# FCFG1 register map
Vendor: Texas Instruments
Peripheral module from a debugger description file (folder CC2650).
Registers are 32-bit, read-only, reset 0xFFFFFFFF unless marked. A register's access mark holds for its fields unless they carry their own. Offsets are as the file gives them; lines under a group give offsets from that group; [hi:lo] are bit positions; {n}, {i} and the like mark numbered series; 'fields as' and 'values as' point back to an identical list; <NAME> marks a mode.

## FCFG1 — Factory configuration area (FCFG1)
0xA0 MISC_CONF_1 reset 0xFFFFFF00 — Misc configurations
  [7:0] DEVICE_MINOR_REV — HW minor revision number (a value of 0xFF is treated equally to 0x00). Value may change without warning.
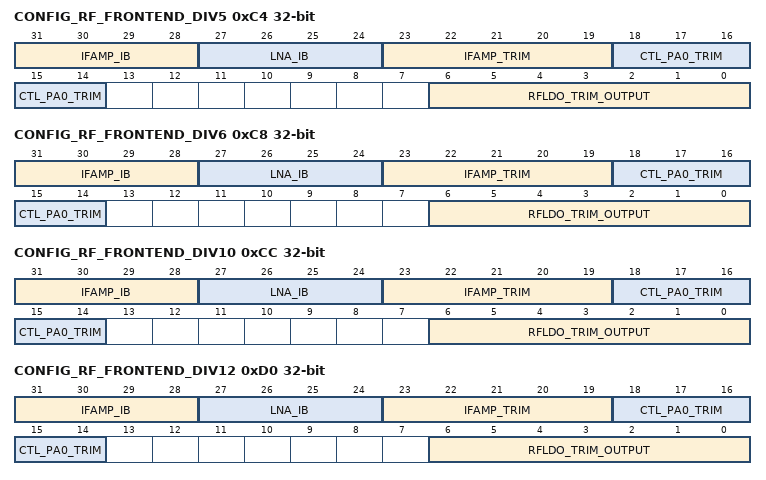
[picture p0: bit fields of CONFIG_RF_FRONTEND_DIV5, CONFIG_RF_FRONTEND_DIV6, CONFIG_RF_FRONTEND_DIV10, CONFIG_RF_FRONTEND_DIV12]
0xC4 CONFIG_RF_FRONTEND_DIV5 — Configuration of RF Frontend in Divide-by-5 Mode Divide-by-5 mode is only available for CC13xx.
  [31:28] IFAMP_IB — Trim value used for ADI_0_RF:IFAMPCTL3.IB. Value is read by RF Core ROM FW during RF Core initialization.
  [27:24] LNA_IB — Trim value for ADI_0_RF:LNACTL2.IB. Value is read by RF Core ROM FW during RF Core initialization.
  [23:19] IFAMP_TRIM — Trim value for ADI_0_RF:IFAMPCTL0.TRIM. Value is read by RF Core ROM FW during RF Core initialization.
  [18:14] CTL_PA0_TRIM — Trim value for ADI_0_RF:PACTL0.TRIM. Value is read by RF Core ROM FW during RF Core initialization.
  [6:0] RFLDO_TRIM_OUTPUT — Trim value for ADI_0_RF:RFLDO1.TRIM_OUT. Value is read by RF Core ROM FW during RF Core initialization.
0xC8 CONFIG_RF_FRONTEND_DIV6 — Configuration of RF Frontend in Divide-by-6 Mode Divide-by-6 mode is only available for CC13xx.
  fields as CONFIG_RF_FRONTEND_DIV5
0xCC CONFIG_RF_FRONTEND_DIV10 — Configuration of RF Frontend in Divide-by-10 Mode Divide-by-10 mode is only available for CC13xx.
  fields as CONFIG_RF_FRONTEND_DIV5
0xD0 CONFIG_RF_FRONTEND_DIV12 — Configuration of RF Frontend in Divide-by-12 Mode Divide-by-12 mode is only available for CC13xx.
  fields as CONFIG_RF_FRONTEND_DIV5
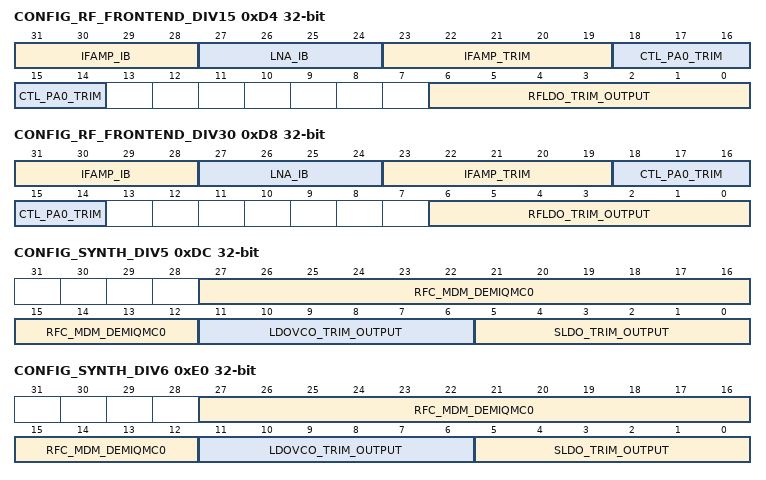
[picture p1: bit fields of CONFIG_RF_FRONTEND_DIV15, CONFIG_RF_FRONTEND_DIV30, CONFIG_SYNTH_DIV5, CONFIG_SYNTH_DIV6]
0xD4 CONFIG_RF_FRONTEND_DIV15 — Configuration of RF Frontend in Divide-by-15 Mode Divide-by-15 mode is only available for CC13xx.
  fields as CONFIG_RF_FRONTEND_DIV5
0xD8 CONFIG_RF_FRONTEND_DIV30 — Configuration of RF Frontend in Divide-by-30 Mode Divide-by-30 mode is only available for CC13xx.
  fields as CONFIG_RF_FRONTEND_DIV5
0xDC CONFIG_SYNTH_DIV5 — Configuration of Synthesizer in Divide-by-5 Mode Divide-by-5 mode is only available for CC13xx.
  [27:12] RFC_MDM_DEMIQMC0 — Trim value for RFC_MDM:DEMIQMC0.GAINFACTOR and RFC_MDM:DEMIQMC0.PHASEFACTOR Value is read by RF Core ROM FW during RF Core initialization.
  [11:6] LDOVCO_TRIM_OUTPUT — Trim value for ADI_1_SYNTH:VCOLDOCTL1.TRIM_OUT. Value is read by RF Core ROM FW during RF Core initialization.
  [5:0] SLDO_TRIM_OUTPUT — Trim value for ADI_1_SYNTH:SLDOCTL1.TRIM_OUT. Value is read by RF Core ROM FW during RF Core initialization.
0xE0 CONFIG_SYNTH_DIV6 — Configuration of Synthesizer in Divide-by-6 Mode Divide-by-6 mode is only available for CC13xx.
  fields as CONFIG_SYNTH_DIV5
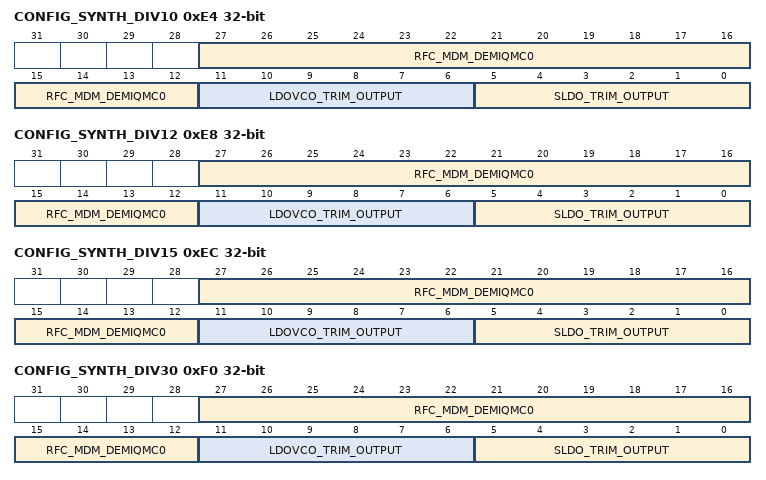
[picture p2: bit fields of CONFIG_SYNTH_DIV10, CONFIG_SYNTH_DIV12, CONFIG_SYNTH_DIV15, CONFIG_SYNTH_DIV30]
0xE4 CONFIG_SYNTH_DIV10 — Configuration of Synthesizer in Divide-by-10 Mode Divide-by-10 mode is only available for CC13xx.
  fields as CONFIG_SYNTH_DIV5
0xE8 CONFIG_SYNTH_DIV12 — Configuration of Synthesizer in Divide-by-12 Mode Divide-by-12 mode is only available for CC13xx.
  fields as CONFIG_SYNTH_DIV5
0xEC CONFIG_SYNTH_DIV15 — Configuration of Synthesizer in Divide-by-15 Mode Divide-by-15 mode is only available for CC13xx.
  fields as CONFIG_SYNTH_DIV5
0xF0 CONFIG_SYNTH_DIV30 — Configuration of Synthesizer in Divide-by-30 Mode Divide-by-30 mode is only available for CC13xx.
  fields as CONFIG_SYNTH_DIV5
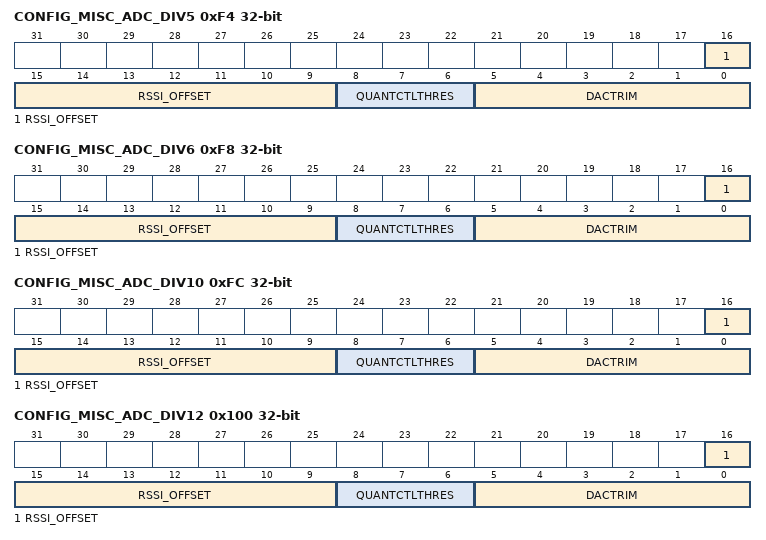
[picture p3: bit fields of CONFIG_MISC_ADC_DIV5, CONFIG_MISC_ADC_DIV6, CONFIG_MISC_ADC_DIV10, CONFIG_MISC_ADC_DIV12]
0xF4 CONFIG_MISC_ADC_DIV5 — Configuration of IFADC in Divide-by-5 Mode Divide-by-5 mode is only available for CC13xx.
  [16:9] RSSI_OFFSET — Value for RSSI measured in production test. Value is read by RF Core ROM FW during RF Core initialization.
  [8:6] QUANTCTLTHRES — Trim value for ADI_0_RF:IFADCQUANT0.TH. Value is read by RF Core ROM FW during RF Core initialization.
  [5:0] DACTRIM — Trim value for ADI_0_RF:IFADCDAC.TRIM. Value is read by RF Core ROM FW during RF Core initialization.
0xF8 CONFIG_MISC_ADC_DIV6 — Configuration of IFADC in Divide-by-6 Mode Divide-by-6 mode is only available for CC13xx.
  fields as CONFIG_MISC_ADC_DIV5
0xFC CONFIG_MISC_ADC_DIV10 — Configuration of IFADC in Divide-by-10 Mode Divide-by-10 mode is only available for CC13xx.
  fields as CONFIG_MISC_ADC_DIV5
0x100 CONFIG_MISC_ADC_DIV12 — Configuration of IFADC in Divide-by-12 Mode Divide-by-12 mode is only available for CC13xx.
  fields as CONFIG_MISC_ADC_DIV5
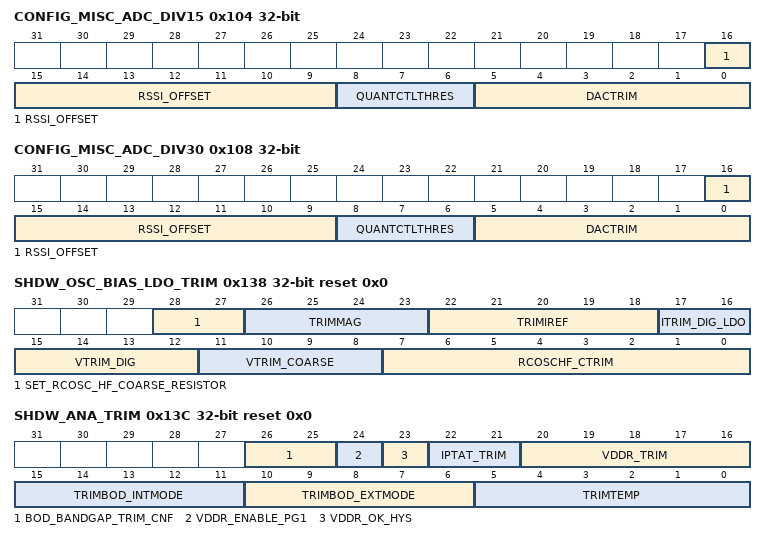
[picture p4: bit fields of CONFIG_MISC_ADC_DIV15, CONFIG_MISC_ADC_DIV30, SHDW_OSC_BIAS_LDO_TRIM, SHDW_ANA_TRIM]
0x104 CONFIG_MISC_ADC_DIV15 — Configuration of IFADC in Divide-by-15 Mode Divide-by-15 mode is only available for CC13xx.
  fields as CONFIG_MISC_ADC_DIV5
0x108 CONFIG_MISC_ADC_DIV30 — Configuration of IFADC in Divide-by-30 Mode Divide-by-30 mode is only available for CC13xx.
  fields as CONFIG_MISC_ADC_DIV5
{0x118+4i} SHDW_DIE_ID_{i} reset 0x0 (i=0..3) — Shadow of EFUSE:DIE_ID_{i}
  [31:0] ID_{32i+31}_{32i} — Shadow of EFUSE:DIE_ID_{i}, ie efuse row number {i+3}
0x138 SHDW_OSC_BIAS_LDO_TRIM reset 0x0 — Shadow of EFUSE:OSC_BIAS_LDO_TRIM
  [28:27] SET_RCOSC_HF_COARSE_RESISTOR — Shadow of EFUSE:OSC_BIAS_LDO_TRIM.SET_RCOSC_HF_COARSE_RESISTOR, ie in efuse row number 11
  [26:23] TRIMMAG — Shadow of EFUSE:OSC_BIAS_LDO_TRIM.TRIMMAG, ie in efuse row number 11
  [22:18] TRIMIREF — Shadow of EFUSE:OSC_BIAS_LDO_TRIM.TRIMIREF, ie in efuse row number 11
  [17:16] ITRIM_DIG_LDO — Shadow of EFUSE:OSC_BIAS_LDO_TRIM.ITRIM_DIG_LDO, ie in efuse row number 11
  [15:12] VTRIM_DIG — Shadow of EFUSE:OSC_BIAS_LDO_TRIM.VTRIM_DIG, ie in efuse row number 11
  [11:8] VTRIM_COARSE — Shadow of EFUSE:OSC_BIAS_LDO_TRIM.VTRIM_COARSE, ie in efuse row number 11
  [7:0] RCOSCHF_CTRIM — Shadow of EFUSE:OSC_BIAS_LDO_TRIM.RCOSCHF_CTRIM, ie in efuse row number 11
0x13C SHDW_ANA_TRIM reset 0x0 — Shadow of EFUSE:ANA_TRIM
  [26:25] BOD_BANDGAP_TRIM_CNF — Shadow of EFUSE:ANA_TRIM.BOD_BANDGAP_TRIM_CNF, ie in efuse row number 12
  [24] VDDR_ENABLE_PG1 — Shadow of EFUSE:ANA_TRIM.VDDR_ENABLE_PG1, ie in efuse row number 12
  [23] VDDR_OK_HYS — Shadow of EFUSE:ANA_TRIM.VDDR_OK_HYS, ie in efuse row number 12
  [22:21] IPTAT_TRIM — Shadow of EFUSE:ANA_TRIM.IPTAT_TRIM, ie in efuse row number 12
  [20:16] VDDR_TRIM — Shadow of EFUSE:ANA_TRIM.VDDR_TRIM, ie in efuse row number 12
  [15:11] TRIMBOD_INTMODE — Shadow of EFUSE:ANA_TRIM.TRIMBOD_INTMODE, ie in efuse row number 12
  [10:6] TRIMBOD_EXTMODE — Shadow of EFUSE:ANA_TRIM.TRIMBOD_EXTMODE, ie in efuse row number 12
  [5:0] TRIMTEMP — Shadow of EFUSE:ANA_TRIM.TRIMTEMP, ie in efuse row number 12
0x164 FLASH_NUMBER reset 0x0
  [31:0] LOT_NUMBER — Number of the manufacturing lot that produced this unit.
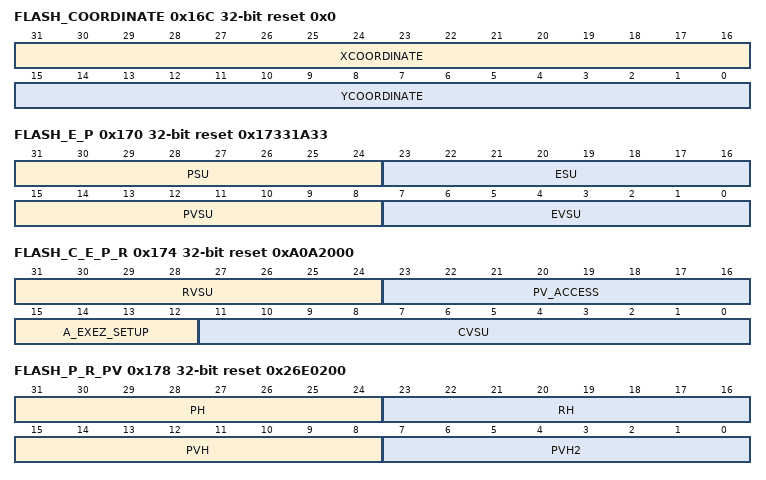
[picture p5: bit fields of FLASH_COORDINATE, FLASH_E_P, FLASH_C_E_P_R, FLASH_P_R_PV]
0x16C FLASH_COORDINATE reset 0x0
  [31:16] XCOORDINATE — X coordinate of this unit on the wafer.
  [15:0] YCOORDINATE — Y coordinate of this unit on the wafer.
0x170 FLASH_E_P reset 0x17331A33 — Flash Erase and Program Setup Time
  [31:24] PSU — Program setup time in cycles. Value will be written to FLASH:FSM_PE_OSU.PGM_OSU by the flash device driver when an erase/program operation is initiated.
  [23:16] ESU — Erase setup time in cycles. Value will be written to FLASH:FSM_PE_OSU.ERA_OSU by the flash device driver when an erase/program operation is initiated.
  [15:8] PVSU — Program verify setup time in cycles. Value will be written to FLASH:FSM_PE_VSU.PGM_VSU by the flash device driver when an erase/program operation is initiated.
  [7:0] EVSU — Erase verify setup time in cycles. Value will be written to FLASH:FSM_PE_VSU.ERA_VSU by the flash device driver when an erase/program operation is initiated.
0x174 FLASH_C_E_P_R reset 0xA0A2000 — Flash Compaction, Execute, Program and Read
  [31:24] RVSU — Repeat verify setup time in cycles. Used for repeated verifies during program and erase. Value will be written to FLASH:FSM_EX_VAL.REP_VSU by the flash device driver when an erase/program operation is initiated.
  [23:16] PV_ACCESS — Program verify EXECUTEZ->data valid time in half-microseconds. Value will be converted to number of FCLK cycles by by flash device driver and the converted value is written to FLASH:FSM_EX_VAL.EXE_VALD when an erase/program operation is initiated..
  [15:12] A_EXEZ_SETUP — Address->EXECUTEZ setup time in cycles. Value will be written to FLASH:FSM_CMP_VSU.ADD_EXZ by the flash device driver when an erase/program operation is initiated..
  [11:0] CVSU — Compaction verify setup time in cycles.
0x178 FLASH_P_R_PV reset 0x26E0200 — Flash Program, Read, and Program Verify
  [31:24] PH — Program hold time in half-microseconds after SAFELV goes low. Value will be converted to number of FCLK cycles by the flash device driver and the converted value is written to FLASH:FSM_P_OH.PGM_OH when an erase/program operation is initiated.
  [23:16] RH — Read hold/mode transition time in cycles. Value will be written to the RD_H field bits[7:0] of the FSM_RD_H register in the flash module by the flash device driver when an erase/program operation is initiated.
  [15:8] PVH — Program verify hold time in half-microseconds after SAFELV goes low. Value will be converted to number of FCLK cycles by the flash device driver and the converted value is written to FLASH:FSM_PE_VH.PGM_VH when an erase/program operation is initiated.
  [7:0] PVH2 — Program verify row switch time in half-microseconds.
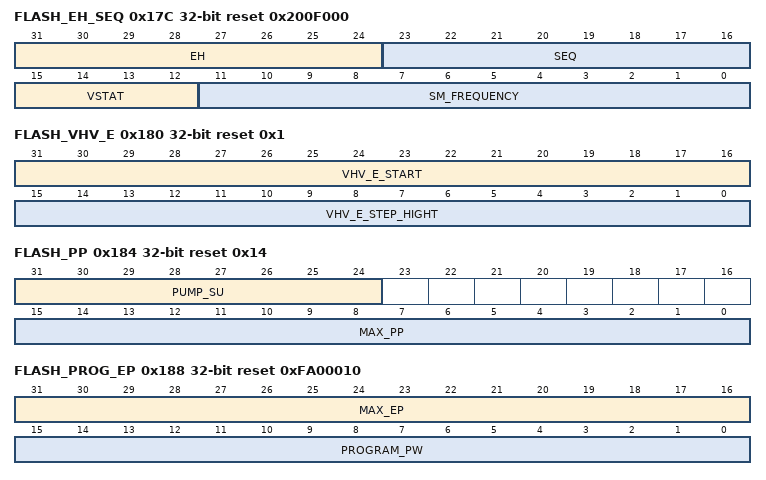
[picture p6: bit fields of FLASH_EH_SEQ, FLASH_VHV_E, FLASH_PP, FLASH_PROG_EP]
0x17C FLASH_EH_SEQ reset 0x200F000 — Flash Erase Hold and Sequence
  [31:24] EH — Erase hold time in half-microseconds after SAFELV goes low. Value will be converted to number of FCLK cycles by the flash device driver and the converted value is written to FLASH:FSM_ERA_OH.ERA_OH when an erase/program operation is initiated.
  [23:16] SEQ — Pump sequence control.
  [15:12] VSTAT — Max number of HCLK cycles allowed for pump brown-out. Value will be written to FLASH:FSM_VSTAT.VSTAT_CNT when an erase/program operation is initiated.
  [11:0] SM_FREQUENCY — Max FCLK frequency allowed for program, erase, and verify reads.
0x180 FLASH_VHV_E reset 0x1 — Flash VHV Erase
  [31:16] VHV_E_START — Starting VHV-Erase CT for stairstep erase. Value will be written to FLASH:FSM_PRG_PUL.BEG_EC_LEVEL when an erase/program operation is initiated.
  [15:0] VHV_E_STEP_HIGHT — Number of VHV CTs to step after each erase pulse (up to the max). The actual FMC register value should be one less than this since the FMC starts counting from zero. Value will be written to FLASH:FSM_EC_STEP_HEIGHT.EC_STEP_HEIGHT when an erase/program operation is initiated.
0x184 FLASH_PP reset 0x14 — Flash Program Pulse
  [31:24] PUMP_SU — Pump read->non-read mode transition time in half-microseconds (mainly for FPES).
  [15:0] MAX_PP — Max program pulse limit per program operation. Value will be written to FLASH:FSM_PRG_PUL.MAX_PRG_PUL when an erase/program operation is initiated.
0x188 FLASH_PROG_EP reset 0xFA00010 — Flash Program and Erase Pulse
  [31:16] MAX_EP — Max erase pulse limit per erase operation. Value will be written to FLASH:FSM_ERA_PUL.MAX_ERA_PUL when an erase/program operation is initiated.
  [15:0] PROGRAM_PW — Program pulse width in half-microseconds. Value will be converted to number of FCLK cycles by the flash device driver and the converted value is written to FLASH:FSM_PRG_PW.PROG_PUL_WIDTH when a erase/program operation is initiated.
0x18C FLASH_ERA_PW reset 0xFA0 — Flash Erase Pulse Width
  [31:0] ERASE_PW — Erase pulse width in half-microseconds. Value will be converted to number of FCLK cycles by the flash device driver and the converted value is written to FLASH:FSM_ERA_PW.FSM_ERA_PW when a erase/program operation is initiated.
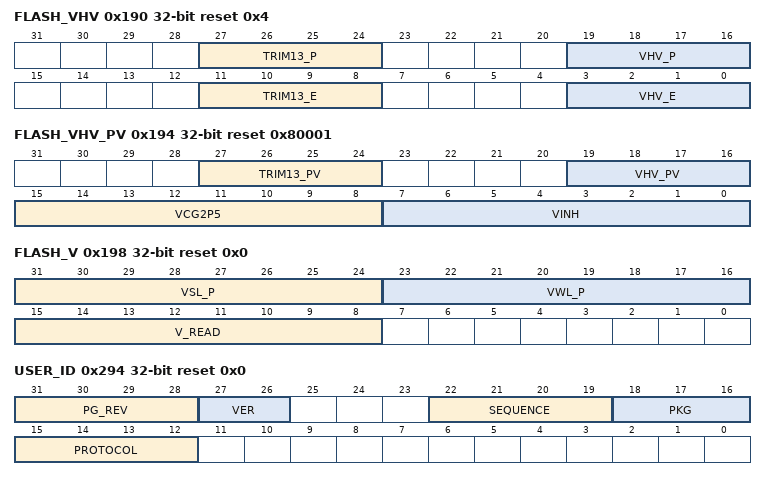
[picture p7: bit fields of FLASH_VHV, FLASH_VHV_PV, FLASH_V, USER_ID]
0x190 FLASH_VHV reset 0x4
  [27:24] TRIM13_P — Value will be written to FLASH:FVHVCT2.TRIM13_P by the flash device driver when an erase/program operation is initiated.
  [19:16] VHV_P — Value will be written to FLASH:FVHVCT2.VHVCT_P by the flash device driver when an erase/program operation is initiated.
  [11:8] TRIM13_E — Value will be written to FLASH:FVHVCT1.TRIM13_E by the flash device driver when an erase/program operation is initiated.
  [3:0] VHV_E — Value will be written to FLASH:FVHVCT1.VHVCT_E by the flash device driver when an erase/program operation is initiated
0x194 FLASH_VHV_PV reset 0x80001 — Flash VHV Program Verify
  [27:24] TRIM13_PV — Value will be written to FLASH:FVHVCT1.TRIM13_PV by the flash device driver when an erase/program operation is initiated.
  [19:16] VHV_PV — Value will be written to FLASH:FVHVCT1.VHVCT_PV by the flash device driver when an erase/program operation is initiated.
  [15:8] VCG2P5 — Control gate voltage during read, read margin, and erase verify. Value will be written to FLASH:FVNVCT.VCG2P5CT by the flash device driver when an erase/program operation is initiated.
  [7:0] VINH — Inhibit voltage applied to unselected columns during programming.
0x198 FLASH_V reset 0x0 — Flash Voltages
  [31:24] VSL_P — Sourceline voltage applied to the selected block during programming. Value will be written to FLASH:FVSLP.VSL_P by the flash device driver when an erase/program operation is initiated.
  [23:16] VWL_P — Wordline voltage applied to the selected half-row during programming. Value will be written to FLASH:FVWLCT.VWLCT_P by the flash device driver when an erase/program operation is initiated.
  [15:8] V_READ — Wordline voltage applied to the selected block during reads and verifies. Value will be written to FLASH:FVREADCT.VREADCT by the flash device driver when an erase/program operation is initiated.
0x294 USER_ID reset 0x0 — User Identification. Reading this register or the ICEPICK_DEVICE_ID register is the only support way of identifying a device. The value of this register will be written to AON_WUC:JTAGUSERCODE by boot FW while in safezone.
  [31:28] PG_REV — PG revision number:
  [27:26] VER — Version number. 0x0: Bits [25:12] of this register has the stated meaning. Any other setting indicate a different encoding of these bits.
  [22:19] SEQUENCE — Sequence. Used to differentiate between marketing/orderable product where other fields of USER_ID is the same (temp range, flash size, voltage range etc)
  [18:16] PKG — Package type. 0x0: 4x4mm 0x1: 5x5mm 0x2: 7x7mm Others values are reserved for future use.
  [15:12] PROTOCOL — Protocols supported. 0x1: BLE 0x2: RF4CE 0x4: Zigbee/6lowpan 0x8: Proprietary More than one protocol can be supported on same device - values above are then combined.
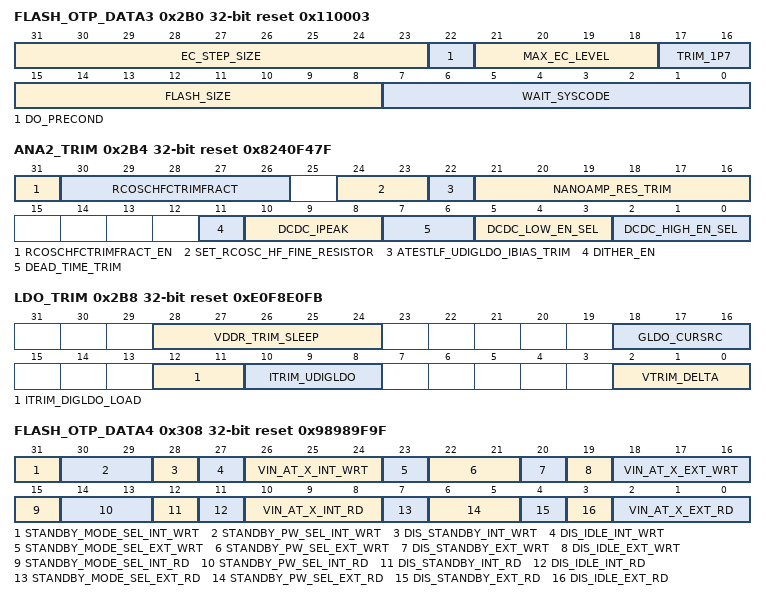
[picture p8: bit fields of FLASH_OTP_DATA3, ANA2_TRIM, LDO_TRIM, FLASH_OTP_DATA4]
0x2B0 FLASH_OTP_DATA3 reset 0x110003
  [31:23] EC_STEP_SIZE — Value will be written to FLASH:FSM_STEP_SIZE.EC_STEP_SIZE by the flash device driver when a erase/program operation is initiated.
  [22] DO_PRECOND — Value will be written to FLASH:FSM_ST_MACHINE.DO_PRECOND by the flash device driver when a erase/program operation is initiated. Note that during a Total Erase operation the flash bank will always be erased with Precondition enabled independent of the value of this FCFG1 bit field.
  [21:18] MAX_EC_LEVEL — Value will be written to FLASH:FSM_ERA_PUL.MAX_EC_LEVEL by the flash device driver when a erase/program operation is initiated.
  [17:16] TRIM_1P7 — Value will be written to FLASH:FSEQPMP.TRIM_1P7 by the flash device driver when a erase/program operation is initiated.
  [15:8] FLASH_SIZE — Value will be written to FLASH:FLASH_SIZE.SECTORS by the boot FW while in safe zone. This register will be write protected by the boot FW by setting FLASH:CFG.CONFIGURED.
  [7:0] WAIT_SYSCODE — Value will be written to FLASH:WAIT_SYSCODE.WAIT_SYSCODE by boot FW code while in safezone.
0x2B4 ANA2_TRIM reset 0x8240F47F — Misc Analog Trim
  [31] RCOSCHFCTRIMFRACT_EN — Value will be written to DDI_0_OSC:CTL1.RCOSCHFCTRIMFRACT_EN by boot FW while in safezone.
  [30:26] RCOSCHFCTRIMFRACT — Value will be written to DDI_0_OSC:CTL1.RCOSCHFCTRIMFRACT by boot FW while in safezone.
  [24:23] SET_RCOSC_HF_FINE_RESISTOR — Value will be written to DDI_0_OSC:ATESTCTL.SET_RCOSC_HF_FINE_RESISTOR by boot FW while in safezone.
  [22] ATESTLF_UDIGLDO_IBIAS_TRIM — Value will be written DDI_0_OSC:ATESTCTL.ATESTLF_UDIGLDO_IBIAS_TRIM by boot FW while in safezone.
  [21:16] NANOAMP_RES_TRIM — Value will be written to DDI_0_OSC:ADCDOUBLERNANOAMPCTL.NANOAMP_RES_TRIM by boot FW while in safezone.
  [11] DITHER_EN — Value will be written to ADI_3_REFSYS:DCDCCTL5.DITHER_EN by boot FW while in safezone.
  [10:8] DCDC_IPEAK — Value will be written to ADI_3_REFSYS:DCDCCTL5.IPEAK by boot FW while in safezone.
  [7:6] DEAD_TIME_TRIM — Value will be written to ADI_3_REFSYS:DCDCCTL4.DEADTIME_TRIM by boot FW while in safezone.
  [5:3] DCDC_LOW_EN_SEL — Value will be written to ADI_3_REFSYS:DCDCCTL4.LOW_EN_SEL by boot FW while in safezone.
  [2:0] DCDC_HIGH_EN_SEL — Value will be written to ADI_3_REFSYS:DCDCCTL4.HIGH_EN_SEL by boot FW while in safezone.
0x2B8 LDO_TRIM reset 0xE0F8E0FB
  [28:24] VDDR_TRIM_SLEEP — Value will be written to ADI_3_REFSYS:DCDCCTL1.VDDR_TRIM_SLEEP by boot FW while in safezone.
  [18:16] GLDO_CURSRC — Value will be written to ADI_3_REFSYS:DCDCCTL0.GLDO_ISRC by boot FW while in safezone.
  [12:11] ITRIM_DIGLDO_LOAD — Value will be written to ADI_2_REFSYS:SOCLDOCTL3.ITRIM_DIGLDO_LOAD by boot FW while in safezone.
  [10:8] ITRIM_UDIGLDO — Value will be written to ADI_2_REFSYS:SOCLDOCTL3.ITRIM_UDIGLDO by boot FW while in safezone.
  [2:0] VTRIM_DELTA — Value will be written to ADI_2_REFSYS:SOCLDOCTL2.VTRIM_DELTA by boot FW while in safezone.
0x2E8 MAC_BLE_0 reset 0x0 — MAC BLE Address 0
  [31:0] ADDR_0_31 — The first 32-bits of the 64-bit MAC BLE address
0x2EC MAC_BLE_1 reset 0x0 — MAC BLE Address 1
  [31:0] ADDR_32_63 — The last 32-bits of the 64-bit MAC BLE address
0x2F0 MAC_15_4_0 reset 0x0 — MAC IEEE 802.15.4 Address 0
  [31:0] ADDR_0_31 — The first 32-bits of the 64-bit MAC 15.4 address
0x2F4 MAC_15_4_1 reset 0x0 — MAC IEEE 802.15.4 Address 1
  [31:0] ADDR_32_63 — The last 32-bits of the 64-bit MAC 15.4 address
0x308 FLASH_OTP_DATA4 reset 0x98989F9F
  [31] STANDBY_MODE_SEL_INT_WRT — If AON_SYSCTL:PWRCTL.EXT_REG_MODE = 0, this value will be written to FLASH:CFG.STANDBY_MODE_SEL by flash device driver FW when a flash write operation is initiated.
  [30:29] STANDBY_PW_SEL_INT_WRT — If AON_SYSCTL:PWRCTL.EXT_REG_MODE = 0, this value will be written to FLASH:CFG.STANDBY_PW_SEL by flash device driver FW when a flash write operation is initiated.
  [28] DIS_STANDBY_INT_WRT — If AON_SYSCTL:PWRCTL.EXT_REG_MODE = 0, this value will be written to FLASH:CFG.DIS_STANDBY by flash device driver FW when a flash write operation is initiated.
  [27] DIS_IDLE_INT_WRT — If AON_SYSCTL:PWRCTL.EXT_REG_MODE = 0, this value will be written to FLASH:CFG.DIS_IDLE by flash device driver FW when a flash write operation is initiated.
  [26:24] VIN_AT_X_INT_WRT — If AON_SYSCTL:PWRCTL.EXT_REG_MODE = 0, this value will be written to FLASH:FSEQPMP.VIN_AT_X by flash device driver FW when a flash write operation is initiated.
  [23] STANDBY_MODE_SEL_EXT_WRT — If AON_SYSCTL:PWRCTL.EXT_REG_MODE = 1, this value will be written to FLASH:CFG.STANDBY_MODE_SEL by flash device driver FW when a flash write operation is initiated.
  [22:21] STANDBY_PW_SEL_EXT_WRT — If AON_SYSCTL:PWRCTL.EXT_REG_MODE = 1, this value will be written to FLASH:CFG.STANDBY_PW_SEL by flash device driver FW when a flash write operation is initiated.
  [20] DIS_STANDBY_EXT_WRT — If AON_SYSCTL:PWRCTL.EXT_REG_MODE = 1, this value will be written to FLASH:CFG.DIS_STANDBY by flash device driver FW when a flash write operation is initiated.
  [19] DIS_IDLE_EXT_WRT — If AON_SYSCTL:PWRCTL.EXT_REG_MODE = 1, this value will be written to FLASH:CFG.DIS_IDLE by flash device driver FW when a flash write operation is initiated.
  [18:16] VIN_AT_X_EXT_WRT — If AON_SYSCTL:PWRCTL.EXT_REG_MODE = 1, this value will be written to FLASH:FSEQPMP.VIN_AT_X by flash device driver FW when a flash write operation is initiated.
  [15] STANDBY_MODE_SEL_INT_RD — If AON_SYSCTL:PWRCTL.EXT_REG_MODE = 0, this value will be written to FLASH:CFG.STANDBY_MODE_SEL both by boot FW while in safezone, and by flash device driver FW after completion of a flash write operation.
  [14:13] STANDBY_PW_SEL_INT_RD — If AON_SYSCTL:PWRCTL.EXT_REG_MODE = 0, this value will be written to FLASH:CFG.STANDBY_PW_SEL both by boot FW while in safezone, and by flash device driver FW after completion of a flash write operation.
  [12] DIS_STANDBY_INT_RD — If AON_SYSCTL:PWRCTL.EXT_REG_MODE = 0, this value will be written to FLASH:CFG.DIS_STANDBY both by boot FW while in safezone, and by flash device driver FW after completion of a flash write operation.
  [11] DIS_IDLE_INT_RD — If AON_SYSCTL:PWRCTL.EXT_REG_MODE = 0, this value will be written to FLASH:CFG.DIS_IDLE both by boot FW while in safezone, and by flash device driver FW after completion of a flash write operation.
  [10:8] VIN_AT_X_INT_RD — If AON_SYSCTL:PWRCTL.EXT_REG_MODE = 0, this value will be written to FLASH:FSEQPMP.VIN_AT_X both by boot FW while in safezone, and by flash device driver FW after completion of a flash write operation.
  [7] STANDBY_MODE_SEL_EXT_RD — If AON_SYSCTL:PWRCTL.EXT_REG_MODE = 1, this value will be written to FLASH:CFG.STANDBY_MODE_SEL both by boot FW while in safezone, and by flash device driver FW after completion of a flash write operation.
  [6:5] STANDBY_PW_SEL_EXT_RD — If AON_SYSCTL:PWRCTL.EXT_REG_MODE = 1, this value will be written to FLASH:CFG.STANDBY_PW_SEL both by boot FW while in safezone, and by flash device driver FW after completion of a flash write operation.
  [4] DIS_STANDBY_EXT_RD — If AON_SYSCTL:PWRCTL.EXT_REG_MODE = 1, this value will be written to FLASH:CFG.DIS_STANDBY both by boot FW while in safezone, and by flash device driver FW after completion of a flash write operation.
  [3] DIS_IDLE_EXT_RD — If AON_SYSCTL:PWRCTL.EXT_REG_MODE = 1, this value will be written to FLASH:CFG.DIS_IDLE both by boot FW while in safezone, and by flash device driver FW after completion of a flash write operation.
  [2:0] VIN_AT_X_EXT_RD — If AON_SYSCTL:PWRCTL.EXT_REG_MODE = 1, this value will be written to FLASH:FSEQPMP.VIN_AT_X both by boot FW while in safezone, and by flash device driver FW after completion of a flash write operation.
0x30C MISC_TRIM reset 0xFFFFFF33 — Miscellaneous Trim Parameters
  [7:0] TEMPVSLOPE — Signed byte value representing the TEMP slope with battery voltage, in degrees C / V, with four fractional bits.
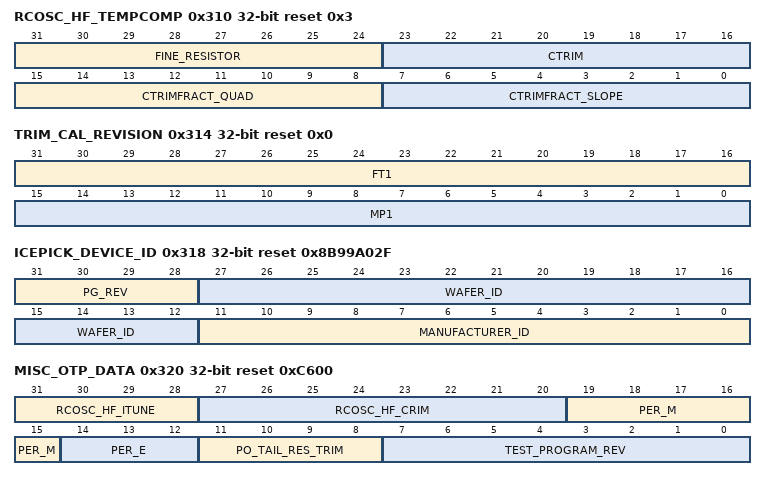
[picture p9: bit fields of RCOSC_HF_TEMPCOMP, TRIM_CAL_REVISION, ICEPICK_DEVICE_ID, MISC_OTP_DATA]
0x310 RCOSC_HF_TEMPCOMP reset 0x3 — RCOSC HF Temperature Compensation
  [31:24] FINE_RESISTOR — Change in FINE_RESISTOR trim
  [23:16] CTRIM — Change in CTRIM trim
  [15:8] CTRIMFRACT_QUAD — Temp compensation quadratic CTRIMFRACT
  [7:0] CTRIMFRACT_SLOPE — Number of CTRIMFRACT codes per 20 degrees C from default temperature
0x314 TRIM_CAL_REVISION reset 0x0 — Production Test Trim and Calibration Revision
  [31:16] FT1 — The revision of the ATE Trim&Calc document used in FT1 in production
  [15:0] MP1 — The revision of the ATE Trim&Calc document used in MP1 in production
0x318 ICEPICK_DEVICE_ID reset 0x8B99A02F — IcePick Device Identification Reading this register or the USER_ID register is the only support way of identifying a device.
  [31:28] PG_REV — Field used to distinguish between different silicon revisions of the device.
  [27:12] WAFER_ID — Field used to identify silicon die.
  [11:0] MANUFACTURER_ID — Manufacturer code. 0x02F: Texas Instruments
0x31C FCFG1_REVISION reset 0x23 — Factory Configuration (FCFG1) Revision
  [31:0] REV — The revision number of the FCFG1 layout. This value will be read by application SW in order to determine which FCFG1 parameters that have valid values. This revision number must be incremented by 1 before any devices are to be produced if the FCFG1 layout has changed since the previous production of devices. Value migth change without warning.
0x320 MISC_OTP_DATA reset 0xC600
  [31:28] RCOSC_HF_ITUNE — Trim value that migth become into use for cc26xx PG2.2 and cc13xx PG2.0. Trim value for DDI_0_OSC:RCOSCHFCTL.RCOSCHF_ITUNE_TRIM.
  [27:20] RCOSC_HF_CRIM — Trim value that migth become into use for cc26xx PG2.2 and cc13xx PG2.0. Trim value for DDI_0_OSC:RCOSCHFCTL.RCOSCHF_CTRIM.
  [19:15] PER_M — Trim value for AON_WUC:OSCCFG.PER_M.
  [14:12] PER_E — Trim value for AON_WUC:OSCCFG.PER_E.
  [11:8] PO_TAIL_RES_TRIM — Trim value for DLO_DTX:PLLCTL1.PO_TAIL_RES_TRIM.
  [7:0] TEST_PROGRAM_REV — The revision of the test program used in the production process when FCFG1 was programmed. Value migth change without warning.
0x344 IOCONF reset 0x0 — IO Configuration
  [6:0] GPIO_CNT — This value is written to IOC:CFG.GPIO_CNT by boot FW while in safezone.
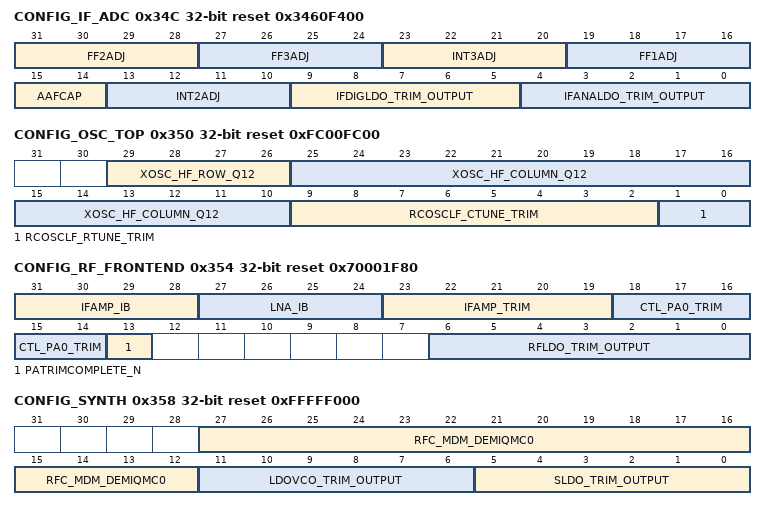
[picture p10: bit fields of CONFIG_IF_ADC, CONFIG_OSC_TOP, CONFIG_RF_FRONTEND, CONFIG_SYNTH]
0x34C CONFIG_IF_ADC reset 0x3460F400 — Configuration of IF_ADC
  [31:28] FF2ADJ — Trim value for ADI_0_RF:IFADCLFCFG1.FF2ADJ. Value is read by RF Core ROM FW during RF Core initialization.
  [27:24] FF3ADJ — Trim value for ADI_0_RF:IFADCLFCFG1.FF3ADJ. Value is read by RF Core ROM FW during RF Core initialization.
  [23:20] INT3ADJ — Trim value for ADI_0_RF:IFADCLFCFG0.INT3ADJ. Value is read by RF Core ROM FW during RF Core initialization.
  [19:16] FF1ADJ — Trim value for ADI_0_RF:IFADCLFCFG0.FF1ADJ. Value is read by RF Core ROM FW during RF Core initialization.
  [15:14] AAFCAP — Trim value for ADI_0_RF:IFADCCTL0.AAFCAP. Value is read by RF Core ROM FW during RF Core initialization.
  [13:10] INT2ADJ — Trim value for ADI_0_RF:IFADCCTL0.INT2ADJ. Value is read by RF Core ROM FW during RF Core initialization.
  [9:5] IFDIGLDO_TRIM_OUTPUT — Trim value for ADI_0_RF:IFDLDO2.TRIM_OUT. Value is read by RF Core ROM FW during RF Core initialization.
  [4:0] IFANALDO_TRIM_OUTPUT — Trim value for ADI_0_RF:IFALDO2.TRIM_OUT. Value is read by RF Core ROM FW during RF Core initialization.
0x350 CONFIG_OSC_TOP reset 0xFC00FC00 — Configuration of OSC
  [29:26] XOSC_HF_ROW_Q12 — Trim value for DDI_0_OSC:ANABYPASSVAL1.XOSC_HF_ROW_Q12.
  [25:10] XOSC_HF_COLUMN_Q12 — Trim value for DDI_0_OSC:ANABYPASSVAL1.XOSC_HF_COLUMN_Q12.
  [9:2] RCOSCLF_CTUNE_TRIM — Trim value for DDI_0_OSC:LFOSCCTL.RCOSCLF_CTUNE_TRIM.
  [1:0] RCOSCLF_RTUNE_TRIM — Trim value for DDI_0_OSC:LFOSCCTL.RCOSCLF_RTUNE_TRIM.
0x354 CONFIG_RF_FRONTEND reset 0x70001F80 — Configuration of RF Frontend in Divide-by-2 Mode
  [31:28] IFAMP_IB — Trim value for ADI_0_RF:IFAMPCTL3.IB. Value is read by RF Core ROM FW during RF Core initialization.
  [27:24] LNA_IB — Trim value for ADI_0_RF:LNACTL2.IB. Value is read by RF Core ROM FW during RF Core initialization.
  [23:19] IFAMP_TRIM — Trim value for ADI_0_RF:IFAMPCTL0.TRIM. Value is read by RF Core ROM FW during RF Core initialization.
  [18:14] CTL_PA0_TRIM — Trim value for ADI_0_RF:PACTL0.TRIM. Value is read by RF Core ROM FW during RF Core initialization.
  [13] PATRIMCOMPLETE_N — Status of PA trim 0: Trimmed 1: Not trimmed
  [6:0] RFLDO_TRIM_OUTPUT — Trim value for ADI_0_RF:RFLDO1.TRIM_OUT. Value is read by RF Core ROM FW during RF Core initialization.
0x358 CONFIG_SYNTH reset 0xFFFFF000 — Configuration of Synthesizer in Divide-by-2 Mode
  [27:12] RFC_MDM_DEMIQMC0 — Trim value for RFC_MDM:DEMIQMC0.GAINFACTOR and RFC_MDM:DEMIQMC0.PHASEFACTOR Value is read by RF Core ROM FW during RF Core initialization only on cc13xx.
  [11:6] LDOVCO_TRIM_OUTPUT — Trim value for ADI_1_SYNTH:VCOLDOCTL1.TRIM_OUT. Value is read by RF Core ROM FW during RF Core initialization.
  [5:0] SLDO_TRIM_OUTPUT — Trim value for ADI_1_SYNTH:SLDOCTL1.TRIM_OUT. Value is read by RF Core ROM FW during RF Core initialization.
0x35C SOC_ADC_ABS_GAIN reset 0x0 — AUX_ADC Gain in Absolute Reference Mode
  [15:0] SOC_ADC_ABS_GAIN_TEMP1 — SOC_ADC gain in absolute reference mode at temperature 1 (30C). Calculated in production test..
0x360 SOC_ADC_REL_GAIN reset 0x0 — AUX_ADC Gain in Relative Reference Mode
  [15:0] SOC_ADC_REL_GAIN_TEMP1 — SOC_ADC gain in relative reference mode at temperature 1 (30C). Calculated in production test..
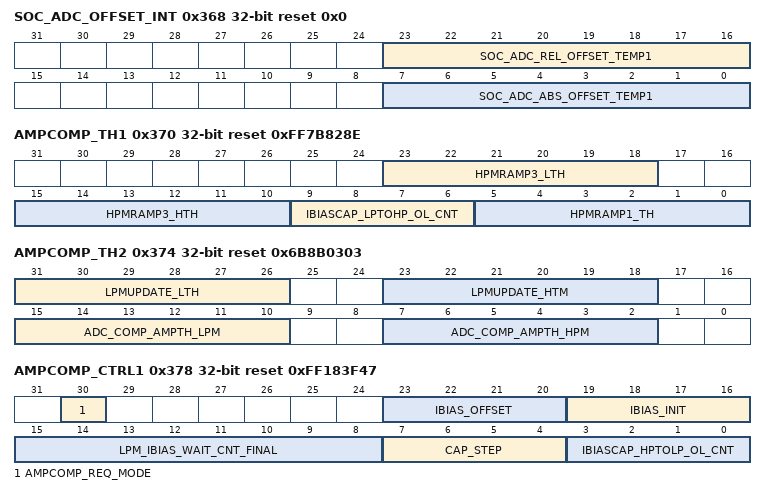
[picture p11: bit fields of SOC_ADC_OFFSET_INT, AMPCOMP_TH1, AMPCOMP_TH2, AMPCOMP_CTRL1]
0x368 SOC_ADC_OFFSET_INT reset 0x0 — AUX_ADC Temperature Offsets in Absolute Reference Mode
  [23:16] SOC_ADC_REL_OFFSET_TEMP1 — SOC_ADC offset in relative reference mode at temperature 1 (30C). Signed 8-bit number. Calculated in production test..
  [7:0] SOC_ADC_ABS_OFFSET_TEMP1 — SOC_ADC offset in absolute reference mode at temperature 1 (30C). Signed 8-bit number. Calculated in production test..
0x36C SOC_ADC_REF_TRIM_AND_OFFSET_EXT reset 0x300080 — AUX_ADC Reference Trim and Offset for External Reference Mode
  [5:0] SOC_ADC_REF_VOLTAGE_TRIM_TEMP1 — Value to write in ADI_4_AUX:ADCREF1.VTRIM at temperature 1 (30C).
0x370 AMPCOMP_TH1 reset 0xFF7B828E — Ampltude Compensation Threashold 1
  [23:18] HPMRAMP3_LTH — HPM Ramp3 low amplitude threshhold. In HPM_RAMP3, if amp > HPMRAMP3_LTH && amp < HPMRAMP3_HTH then move on HPM_UPDATE.
  [15:10] HPMRAMP3_HTH — In HPM_RAMP3, if amp > HPMRAMP3_LTH && amp < HPMRAMP3_HTH then move on to HPM_UPDATE.
  [9:6] IBIASCAP_LPTOHP_OL_CNT — During XOSC mode transition, CAP trim and IBIAS trim should be modified by this amount. IBIAS and CAP trim open loop count. CAP_REM is remainder of the CAP that is left to reach the final cap value.
  [5:0] HPMRAMP1_TH — During XOSC mode transition, CAP trim and IBIAS trim should be modified by this amount. IBIAS and CAP trim open loop count. CAP_REM is remainder of the CAP that is left to reach the final cap value.
0x374 AMPCOMP_TH2 reset 0x6B8B0303 — Ampltude Compensation Threashold 2
  [31:26] LPMUPDATE_LTH — LPM Update low amplitude threshhold. if amp > LPMUPDATE_LTH && amp < LPMUPDATE_HTH then move on.
  [23:18] LPMUPDATE_HTM — LPM Update high amplitude threshhold. if amp > LPMUPDATE_LTH && amp < LPMUPDATE_HTH then move on.
  [15:10] ADC_COMP_AMPTH_LPM — When ADC is forced in comparator mode, this value is used as OPAMP's threshold during LPM_UPDATE mode. Actual amplitude is compared against this threshhold to generate 1-bit adc_threshholdmet indicator output.
  [7:2] ADC_COMP_AMPTH_HPM — When ADC is forced in comparator mode, this value is used as OPAMP's threshold during HPM_UPDATE mode. Actual amplitude is compared against this threshhold to generate 1-bit adc_threshholdmet indicator output.
0x378 AMPCOMP_CTRL1 reset 0xFF183F47 — Amplitude Compensation Control
  [30] AMPCOMP_REQ_MODE — Trim value for DDI_0_OSC:AMPCOMPCTL.AMPCOMP_REQ_MODE.
  [23:20] IBIAS_OFFSET — Offset values of XOSC IBIAS trim. IBIAS trim value would always be greater than or equal to this offset in both HPM and LPM.
  [19:16] IBIAS_INIT — Initial value of XOSC IBIAS trim. During ramping up, IBIAS is set to IBIAS_OFFSET + IBIAS_INIT.
  [15:8] LPM_IBIAS_WAIT_CNT_FINAL — FSM waits for ddi_lpm_ibias_wait_cnt_final clock cycles in IDAC_DECREMENT_WITH_MEASURE states in order to compensate slow response of the xtal. 8-bits.
  [7:4] CAP_STEP — Step size of XOSC CAP trim (both Q1 and Q2) during XOSC mode transition. Can vary from 6 to 12. Other values are possible but not valid.
  [3:0] IBIASCAP_HPTOLP_OL_CNT — During HPM to LPM transition, CAP trim and IBIAS trim should be modified by this amount. IBIAS and CAP trim open loop count. CAP_REM is remainder of the CAP that is left to reach the final cap value. Do not need to program this. CAP_TRIM = CAP_INIT - CAP_STEP*IBIASCAP_HPTOLP_OL_CNT - CAP_REM; IBIAS_TRIM = IBIAS_INIT - 1*IBIASCAP_HPTOLP_OL_CNT; Here, cap_init is decimal conversion of cap_init_col and cap_init_row.
0x37C ANABYPASS_VALUE2 reset 0xFFFFC3FF — Analog Bypass Value for OSC
  [13:0] XOSC_HF_IBIASTHERM — Value of xosc_hf_ibiastherm when oscdig is bypassed.
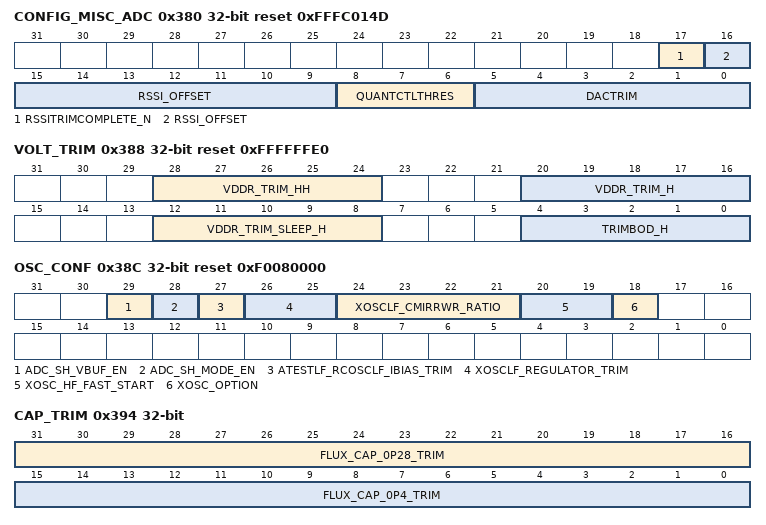
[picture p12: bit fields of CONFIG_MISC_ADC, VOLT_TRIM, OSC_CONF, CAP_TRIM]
0x380 CONFIG_MISC_ADC reset 0xFFFC014D — Configuration of IFADC in Divide-by-2 Mode
  [17] RSSITRIMCOMPLETE_N — Status of RSSI trim 0: Trimmed 1: Not trimmed
  [16:9] RSSI_OFFSET — Value for RSSI measured in production test. Value is read by RF Core ROM FW during RF Core initialization.
  [8:6] QUANTCTLTHRES — Trim value for ADI_0_RF:IFADCQUANT0.TH. Value is read by RF Core ROM FW during RF Core initialization.
  [5:0] DACTRIM — Trim value for ADI_0_RF:IFADCDAC.TRIM. Value is read by RF Core ROM FW during RF Core initialization.
0x388 VOLT_TRIM reset 0xFFFFFFE0 — Voltage Trim
  [28:24] VDDR_TRIM_HH — Trim value for 1.94V VDDR found in production test (for CC13xx high PA output power only).
  [20:16] VDDR_TRIM_H — Trim value for 1.85V VDDR found in production test (for external VDDR load mode)
  [12:8] VDDR_TRIM_SLEEP_H — Trim value for 1.75V VDDR recharge target found in production test (for external VDDR load mode).
  [4:0] TRIMBOD_H — Trim value for 2.0V VDDS BOD target found in production test.
0x38C OSC_CONF reset 0xF0080000 — OSC Configuration
  [29] ADC_SH_VBUF_EN — Trim value for DDI_0_OSC:ADCDOUBLERNANOAMPCTL.ADC_SH_VBUF_EN.
  [28] ADC_SH_MODE_EN — Trim value for DDI_0_OSC:ADCDOUBLERNANOAMPCTL.ADC_SH_MODE_EN.
  [27] ATESTLF_RCOSCLF_IBIAS_TRIM — Trim value for DDI_0_OSC:ATESTCTL.ATESTLF_RCOSCLF_IBIAS_TRIM.
  [26:25] XOSCLF_REGULATOR_TRIM — Trim value for DDI_0_OSC:LFOSCCTL.XOSCLF_REGULATOR_TRIM.
  [24:21] XOSCLF_CMIRRWR_RATIO — Trim value for DDI_0_OSC:LFOSCCTL.XOSCLF_CMIRRWR_RATIO.
  [20:19] XOSC_HF_FAST_START — Trim value for DDI_0_OSC:CTL1.XOSC_HF_FAST_START. This trim value is not relevant for PG1 devices.
  [18] XOSC_OPTION — 0: XOSC_HF unavailable (may not be bonded out) 1: XOSC_HF available (default)
0x394 CAP_TRIM — Capasitor Trim
  [31:16] FLUX_CAP_0P28_TRIM — Reserved storage of measurement value on 0.28um pitch FLUX CAP (measured in production test)
  [15:0] FLUX_CAP_0P4_TRIM — Reserved storage of measurement value on 0.4um pitch FLUX CAP (measured in production test)
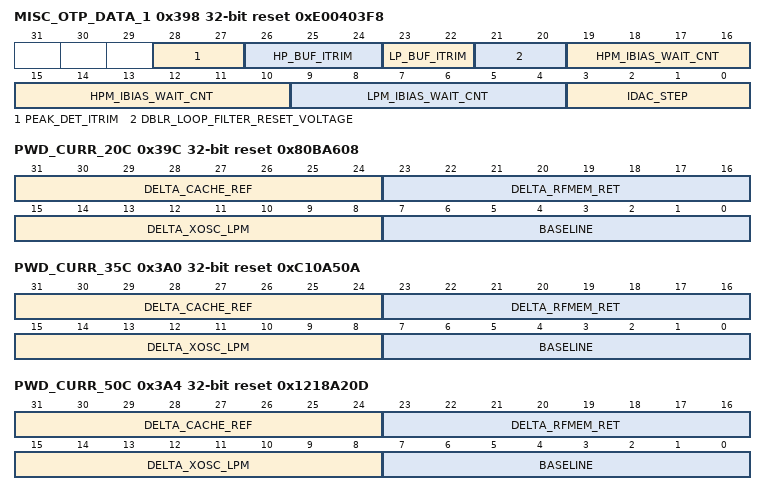
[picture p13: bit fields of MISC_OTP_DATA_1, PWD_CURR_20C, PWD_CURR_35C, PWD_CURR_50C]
0x398 MISC_OTP_DATA_1 reset 0xE00403F8 — Misc OSC Control
  [28:27] PEAK_DET_ITRIM — Trim value for DDI_0_OSC:XOSCHFCTL.PEAK_DET_ITRIM.
  [26:24] HP_BUF_ITRIM — Trim value for DDI_0_OSC:XOSCHFCTL.HP_BUF_ITRIM.
  [23:22] LP_BUF_ITRIM — Trim value for DDI_0_OSC:XOSCHFCTL.LP_BUF_ITRIM.
  [21:20] DBLR_LOOP_FILTER_RESET_VOLTAGE — Trim value for DDI_0_OSC:ADCDOUBLERNANOAMPCTL.DBLR_LOOP_FILTER_RESET_VOLTAGE.
  [19:10] HPM_IBIAS_WAIT_CNT — Trim value for DDI_0_OSC:RADCEXTCFG.HPM_IBIAS_WAIT_CNT.
  [9:4] LPM_IBIAS_WAIT_CNT — Trim value for DDI_0_OSC:RADCEXTCFG.LPM_IBIAS_WAIT_CNT.
  [3:0] IDAC_STEP — Trim value for DDI_0_OSC:RADCEXTCFG.IDAC_STEP.
0x39C PWD_CURR_20C reset 0x80BA608 — Power Down Current Control 20C
  [31:24] DELTA_CACHE_REF — Additional maximum current, in units of 1uA, with cache retention
  [23:16] DELTA_RFMEM_RET — Additional maximum current, in 1uA units, with RF memory retention
  [15:8] DELTA_XOSC_LPM — Additional maximum current, in units of 1uA, with XOSC_HF on in low-power mode
  [7:0] BASELINE — Worst-case baseline maximum powerdown current, in units of 0.5uA
0x3A0 PWD_CURR_35C reset 0xC10A50A — Power Down Current Control 35C
  fields as PWD_CURR_20C
0x3A4 PWD_CURR_50C reset 0x1218A20D — Power Down Current Control 50C
  fields as PWD_CURR_20C
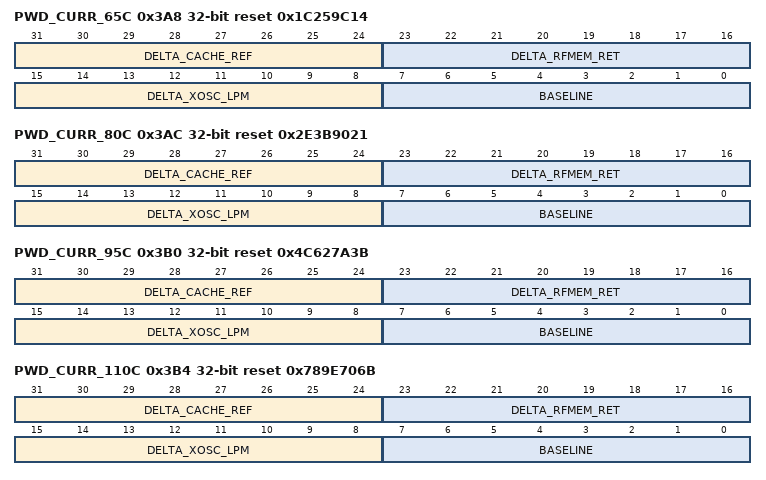
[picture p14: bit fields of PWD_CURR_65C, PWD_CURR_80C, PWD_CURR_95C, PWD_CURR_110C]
0x3A8 PWD_CURR_65C reset 0x1C259C14 — Power Down Current Control 65C
  fields as PWD_CURR_20C
0x3AC PWD_CURR_80C reset 0x2E3B9021 — Power Down Current Control 80C
  fields as PWD_CURR_20C
0x3B0 PWD_CURR_95C reset 0x4C627A3B — Power Down Current Control 95C
  fields as PWD_CURR_20C
0x3B4 PWD_CURR_110C reset 0x789E706B — Power Down Current Control 110C
  fields as PWD_CURR_20C
0x3B8 PWD_CURR_125C reset 0xADE1809A — Power Down Current Control 125C
  fields as PWD_CURR_20C
